AUTOSAR XML (schema 4-3-0)
package /cdd_lfic
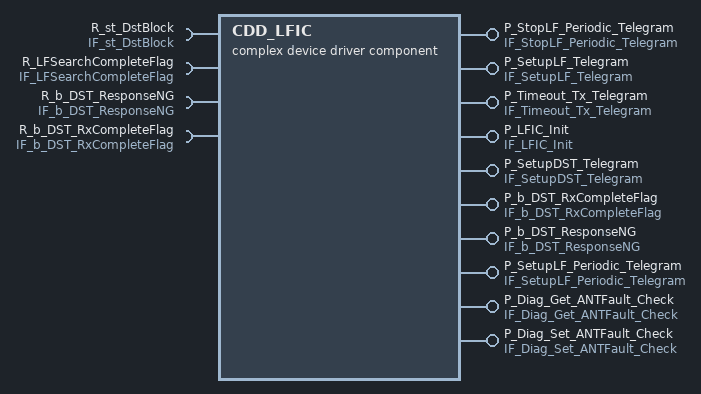
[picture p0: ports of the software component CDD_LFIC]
  complex device driver sw component type CDD_LFIC
    5 x provide port, all with server-com-spec{operation=CS, queue-length=1}:
      P_StopLF_Periodic_Telegram: provided-interface=IF_StopLF_Periodic_Telegram
      P_SetupLF_Telegram: provided-interface=IF_SetupLF_Telegram
      P_Timeout_Tx_Telegram: provided-interface=IF_Timeout_Tx_Telegram
      P_LFIC_Init: provided-interface=IF_LFIC_Init
      P_SetupDST_Telegram: provided-interface=IF_SetupDST_Telegram
    require port R_st_DstBlock: required-interface=IF_st_DstBlock
    provide port P_b_DST_RxCompleteFlag: provided-interface=IF_b_DST_RxCompleteFlag
    provide port P_b_DST_ResponseNG: provided-interface=IF_b_DST_ResponseNG
    provide port P_SetupLF_Periodic_Telegram: server-com-spec{operation=CS, queue-length=1}, provided-interface=IF_SetupLF_Periodic_Telegram
    require port R_LFSearchCompleteFlag: required-interface=IF_LFSearchCompleteFlag
    require port R_b_DST_ResponseNG: required-interface=IF_b_DST_ResponseNG
    require port R_b_DST_RxCompleteFlag: required-interface=IF_b_DST_RxCompleteFlag
    provide port P_Diag_Get_ANTFault_Check: server-com-spec{operation=CS, queue-length=1}, provided-interface=IF_Diag_Get_ANTFault_Check
    provide port P_Diag_Set_ANTFault_Check: server-com-spec{operation=CS, queue-length=1}, provided-interface=IF_Diag_Set_ANTFault_Check
    behavior InternalBehavior
      7 x operation invoked event:
        OIE_RE_SetupLF_Telegram_P_SetupLF_Telegram_CS: start-on-event=RE_SetupLF_Telegram, operation=P_SetupLF_Telegram.CS
        OIE_RE_Timeout_Tx_Telegram_P_Timeout_Tx_Telegram_CS: start-on-event=RE_Timeout_Tx_Telegram, operation=P_Timeout_Tx_Telegram.CS
        OIE_RE_LFIC_Init_IF_LFIC_Init_CS: start-on-event=RE_LFIC_Init, operation=P_LFIC_Init.CS
        OIE_RE_SetupLF_Periodic_Telegram_P_SetupLF_Periodic_Telegram_CS: start-on-event=RE_SetupLF_Periodic_Telegram, operation=P_SetupLF_Periodic_Telegram.CS
        OIE_RE_StopLF_Periodic_Telegram_P_StopLF_Periodic_Telegram_CS: start-on-event=RE_StopLF_Periodic_Telegram, operation=P_StopLF_Periodic_Telegram.CS
        OIE_RE_Diag_Set_ANTFault_Check_P_Diag_Set_ANTFault_Check_CS: start-on-event=RE_Diag_Set_ANTFault_Check, operation=P_Diag_Set_ANTFault_Check.CS
        OIE_RE_Diag_Get_ANTFault_Check_P_Diag_Get_ANTFault_Check_CS: start-on-event=RE_Diag_Get_ANTFault_Check, operation=P_Diag_Get_ANTFault_Check.CS
      10 x runnable, all with can-be-invoked-concurrently=true:
        RE_SetupLF_Telegram
        RE_Timeout_Tx_Telegram
        RE_LFSearch_Complete
        RE_LFIC_Init
        RE_SetupLF_Periodic_Telegram
        RE_StopLF_Periodic_Telegram
        RE_Diag_Set_ANTFault_Check
        RE_Diag_Get_ANTFault_Check
        RE_DST_RX_ISR: symbol=DST_RX_ISR
        RE_SetupDST_Telegram
